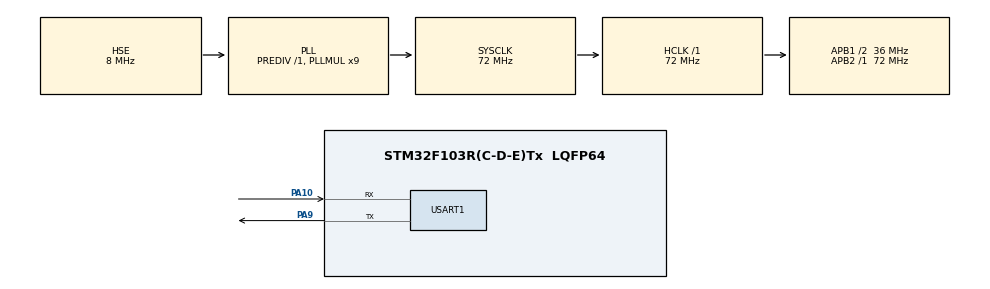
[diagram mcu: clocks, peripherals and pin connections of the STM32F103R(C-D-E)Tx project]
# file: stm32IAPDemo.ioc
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ADC1.Channel-0\#ChannelRegularConversion=ADC_CHANNEL_TEMPSENSOR
ADC1.ContinuousConvMode=ENABLE
ADC1.NbrOfConversionFlag=1
ADC1.Rank-0\#ChannelRegularConversion=1
ADC1.SamplingTime-0\#ChannelRegularConversion=ADC_SAMPLETIME_239CYCLES_5
ADC1.master=1
Dma.ADC1.0.Direction=DMA_PERIPH_TO_MEMORY
Dma.ADC1.0.Instance=DMA1_Channel1
Dma.ADC1.0.MemDataAlignment=DMA_MDATAALIGN_WORD
Dma.ADC1.0.MemInc=DMA_MINC_ENABLE
Dma.ADC1.0.Mode=DMA_NORMAL
Dma.ADC1.0.PeriphDataAlignment=DMA_PDATAALIGN_HALFWORD
Dma.ADC1.0.PeriphInc=DMA_PINC_DISABLE
Dma.ADC1.0.Priority=DMA_PRIORITY_LOW
Dma.Request0=ADC1
FREERTOS.Queues01=cmdRxQueue,512,uint8_t,0,Static,cmdRxQueueBuffer,cmdRxQueueControlBlock;cmdTxQueue,512,uint8_t,0,Static,cmdTxQueueBuffer,cmdTxQueueControlBlock
FREERTOS.Tasks01=defaultTask,24,128,StartDefaultTask,Default,NULL,Dynamic,NULL,NULL;taskParseCmd,40,1024,StartTaskParseCmd,Default,NULL,Dynamic,NULL,NULL;taskFeedWD,55,128,StartTaskFeedWD,Default,NULL,Dynamic,NULL,NULL
FREERTOS.Timers01=cmdReceiveTimeout,CmdReceiveTimeoutCallback,osTimerOnce,Default,NULL,Static,cmdReceiveTimeoutControlBlock
FREERTOS.configTOTAL_HEAP_SIZE=10240
IWDG.Prescaler=IWDG_PRESCALER_32
Mcu.Family=STM32F1
Mcu.Name=STM32F103R(C-D-E)Tx
Mcu.Package=LQFP64
NVIC.DMA1_Channel1_IRQn=true\:5\:0\:false\:false\:true\:true\:false\:true
NVIC.PriorityGroup=NVIC_PRIORITYGROUP_4
NVIC.TIM1_UP_IRQn=true\:0\:0\:false\:false\:true\:false\:false\:true
NVIC.TimeBase=TIM1_UP_IRQn
NVIC.TimeBaseIP=TIM1
NVIC.USART1_IRQn=true\:5\:0\:false\:false\:true\:true\:true\:true
PA10.GPIO_PuPd=GPIO_PULLUP
PA10.Mode=Asynchronous
PA10.Signal=USART1_RX
PA13.Mode=JTAG_5_pins
PA13.Signal=SYS_JTMS-SWDIO
PA14.Mode=JTAG_5_pins
PA14.Signal=SYS_JTCK-SWCLK
PA15.Mode=JTAG_5_pins
PA15.Signal=SYS_JTDI
PA9.Mode=Asynchronous
PA9.Signal=USART1_TX
PB3.Mode=JTAG_5_pins
PB3.Signal=SYS_JTDO-TRACESWO
PB4.Mode=JTAG_5_pins
PB4.Signal=SYS_NJTRST
PD0-OSC_IN.Mode=HSE-External-Oscillator
PD0-OSC_IN.Signal=RCC_OSC_IN
PD1-OSC_OUT.Mode=HSE-External-Oscillator
PD1-OSC_OUT.Signal=RCC_OSC_OUT
ProjectManager.HeapSize=0x200
ProjectManager.StackSize=0x400
ProjectManager.TargetToolchain=MDK-ARM V5.27
RCC.ADCPresc=RCC_ADCPCLK2_DIV6
RCC.AHBFreq_Value=72000000
RCC.APB1CLKDivider=RCC_HCLK_DIV2
RCC.APB1Freq_Value=36000000
RCC.APB1TimFreq_Value=72000000
RCC.APB2Freq_Value=72000000
RCC.APB2TimFreq_Value=72000000
RCC.HCLKFreq_Value=72000000
RCC.PLLMUL=RCC_PLL_MUL9
RCC.PLLSourceVirtual=RCC_PLLSOURCE_HSE
RCC.SYSCLKFreq_VALUE=72000000
RCC.SYSCLKSource=RCC_SYSCLKSOURCE_PLLCLK
RCC.USBFreq_Value=72000000
USART1.VirtualMode=VM_ASYNC
VP_ADC1_TempSens_Input.Mode=IN-TempSens
VP_FREERTOS_VS_CMSIS_V2.Mode=CMSIS_V2
VP_IWDG_VS_IWDG.Mode=IWDG_Activate
VP_RTC_VS_RTC_Activate.Mode=RTC_Enabled
VP_RTC_VS_RTC_Calendar.Mode=RTC_Calendar
VP_SYS_VS_tim1.Mode=TIM1
board=custom

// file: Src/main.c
/* USER CODE BEGIN Header */
/**
  ******************************************************************************
  * @file           : main.c
  * @brief          : Main program body
  ******************************************************************************
  * @attention
  *
  * <h2><center>&copy; Copyright (c) 2020 STMicroelectronics.
  * All rights reserved.</center></h2>
  *
  * This software component is licensed by ST under Ultimate Liberty license
  * SLA0044, the "License"; You may not use this file except in compliance with
  * the License. You may obtain a copy of the License at:
  *                             www.st.com/SLA0044
  *
  ******************************************************************************
  */
/* USER CODE END Header */

#include "main.h"
#include "cmsis_os.h"
#include "adc.h"
#include "dma.h"
#include "iwdg.h"
#include "rtc.h"
#include "usart.h"
#include "gpio.h"

void SystemClock_Config(void);
void MX_FREERTOS_Init(void);

int main(void)
{
  /* USER CODE BEGIN 1 */
	#ifndef BOOTLOADER_APPLICATION
		SCB->VTOR = APPLICATION_ADDRESS;
	#endif
  /* USER CODE END 1 */

  /* MCU Configuration--------------------------------------------------------*/

  /* Reset of all peripherals, Initializes the Flash interface and the Systick. */
  HAL_Init();

  /* Configure the system clock */
  SystemClock_Config();

  /* Initialize all configured peripherals */
  MX_GPIO_Init();
  MX_USART1_UART_Init();
  MX_RTC_Init();
  MX_IWDG_Init();
  MX_DMA_Init();
  MX_ADC1_Init();
  /* USER CODE BEGIN 2 */
	#ifdef BOOTLOADER_APPLICATION
	CheckUpdate();
	#endif
	// https://controllerstech.com/how-to-read-multichannel-adc-in-stm32/
	// https://controllerstech.com/stm32-adc-multi-channels/
	HAL_ADCEx_Calibration_Start(&hadc1); // we need to start the calibration before the adc start
	HAL_ADC_Start_DMA (&hadc1, &temperature_adc, 1);
	LL_USART_EnableIT_RXNE(USART1);
  /* USER CODE END 2 */

  /* Call init function for freertos objects (in freertos.c) */
  MX_FREERTOS_Init();

  /* Start scheduler */
  osKernelStart();

  /* We should never get here as control is now taken by the scheduler */

  /* Infinite loop */
  while (1)
  {

  }
}

void SystemClock_Config(void)
{
  RCC_OscInitTypeDef RCC_OscInitStruct = {0};
  RCC_ClkInitTypeDef RCC_ClkInitStruct = {0};
  RCC_PeriphCLKInitTypeDef PeriphClkInit = {0};

  /** Initializes the CPU, AHB and APB busses clocks
  */
  RCC_OscInitStruct.OscillatorType = RCC_OSCILLATORTYPE_LSI|RCC_OSCILLATORTYPE_HSE;
  RCC_OscInitStruct.HSEState = RCC_HSE_ON;
  RCC_OscInitStruct.HSEPredivValue = RCC_HSE_PREDIV_DIV1;
  RCC_OscInitStruct.HSIState = RCC_HSI_ON;
  RCC_OscInitStruct.LSIState = RCC_LSI_ON;
  RCC_OscInitStruct.PLL.PLLState = RCC_PLL_ON;
  RCC_OscInitStruct.PLL.PLLSource = RCC_PLLSOURCE_HSE;
  RCC_OscInitStruct.PLL.PLLMUL = RCC_PLL_MUL9;
  if (HAL_RCC_OscConfig(&RCC_OscInitStruct) != HAL_OK)
  {
    Error_Handler();
  }
  /** Initializes the CPU, AHB and APB busses clocks
  */
  RCC_ClkInitStruct.ClockType = RCC_CLOCKTYPE_HCLK|RCC_CLOCKTYPE_SYSCLK
                              |RCC_CLOCKTYPE_PCLK1|RCC_CLOCKTYPE_PCLK2;
  RCC_ClkInitStruct.SYSCLKSource = RCC_SYSCLKSOURCE_PLLCLK;
  RCC_ClkInitStruct.AHBCLKDivider = RCC_SYSCLK_DIV1;
  RCC_ClkInitStruct.APB1CLKDivider = RCC_HCLK_DIV2;
  RCC_ClkInitStruct.APB2CLKDivider = RCC_HCLK_DIV1;

  if (HAL_RCC_ClockConfig(&RCC_ClkInitStruct, FLASH_LATENCY_2) != HAL_OK)
  {
    Error_Handler();
  }
  PeriphClkInit.PeriphClockSelection = RCC_PERIPHCLK_RTC|RCC_PERIPHCLK_ADC;
  PeriphClkInit.RTCClockSelection = RCC_RTCCLKSOURCE_LSI;
  PeriphClkInit.AdcClockSelection = RCC_ADCPCLK2_DIV6;
  if (HAL_RCCEx_PeriphCLKConfig(&PeriphClkInit) != HAL_OK)
  {
    Error_Handler();
  }
}

void HAL_TIM_PeriodElapsedCallback(TIM_HandleTypeDef *htim)
{
  if (htim->Instance == TIM1) {
    HAL_IncTick();
  }
}

void Error_Handler(void)
{
}

/************************ (C) COPYRIGHT STMicroelectronics *****END OF FILE****/

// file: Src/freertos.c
/* USER CODE BEGIN Header */
/**
  ******************************************************************************
  * File Name          : freertos.c
  * Description        : Code for freertos applications
  ******************************************************************************
  * @attention
  *
  * <h2><center>&copy; Copyright (c) 2020 STMicroelectronics.
  * All rights reserved.</center></h2>
  *
  * This software component is licensed by ST under Ultimate Liberty license
  * SLA0044, the "License"; You may not use this file except in compliance with
  * the License. You may obtain a copy of the License at:
  *                             www.st.com/SLA0044
  *
  ******************************************************************************
  */
/* USER CODE END Header */

#include "FreeRTOS.h"
#include "task.h"
#include "main.h"
#include "cmsis_os.h"

typedef StaticQueue_t osStaticMessageQDef_t;
typedef StaticTimer_t osStaticTimerDef_t;
osThreadId_t defaultTaskHandle;
osThreadId_t taskParseCmdHandle;
osThreadId_t taskFeedWDHandle;
osMessageQueueId_t cmdRxQueueHandle;
uint8_t cmdRxQueueBuffer[ 512 * sizeof( uint8_t ) ];
osStaticMessageQDef_t cmdRxQueueControlBlock;
osMessageQueueId_t cmdTxQueueHandle;
uint8_t cmdTxQueueBuffer[ 512 * sizeof( uint8_t ) ];
osStaticMessageQDef_t cmdTxQueueControlBlock;
osTimerId_t cmdReceiveTimeoutHandle;
osStaticTimerDef_t cmdReceiveTimeoutControlBlock;

void StartDefaultTask(void *argument);
void StartTaskParseCmd(void *argument);
void StartTaskFeedWD(void *argument);
void CmdReceiveTimeoutCallback(void *argument);

void MX_FREERTOS_Init(void); /* (MISRA C 2004 rule 8.1) */

void MX_FREERTOS_Init(void) {
osKernelInitialize();

  /* Create the timer(s) */
  /* definition and creation of cmdReceiveTimeout */
  const osTimerAttr_t cmdReceiveTimeout_attributes = {
    .name = "cmdReceiveTimeout",
    .cb_mem = &cmdReceiveTimeoutControlBlock,
    .cb_size = sizeof(cmdReceiveTimeoutControlBlock),
  };
  cmdReceiveTimeoutHandle = osTimerNew(CmdReceiveTimeoutCallback, osTimerOnce, NULL, &cmdReceiveTimeout_attributes);

  /* Create the queue(s) */
  /* definition and creation of cmdRxQueue */
  const osMessageQueueAttr_t cmdRxQueue_attributes = {
    .name = "cmdRxQueue",
    .cb_mem = &cmdRxQueueControlBlock,
    .cb_size = sizeof(cmdRxQueueControlBlock),
    .mq_mem = &cmdRxQueueBuffer,
    .mq_size = sizeof(cmdRxQueueBuffer)
  };
  cmdRxQueueHandle = osMessageQueueNew (512, sizeof(uint8_t), &cmdRxQueue_attributes);

  /* definition and creation of cmdTxQueue */
  const osMessageQueueAttr_t cmdTxQueue_attributes = {
    .name = "cmdTxQueue",
    .cb_mem = &cmdTxQueueControlBlock,
    .cb_size = sizeof(cmdTxQueueControlBlock),
    .mq_mem = &cmdTxQueueBuffer,
    .mq_size = sizeof(cmdTxQueueBuffer)
  };
  cmdTxQueueHandle = osMessageQueueNew (512, sizeof(uint8_t), &cmdTxQueue_attributes);

  /* Create the thread(s) */
  /* definition and creation of defaultTask */
  const osThreadAttr_t defaultTask_attributes = {
    .name = "defaultTask",
    .priority = (osPriority_t) osPriorityNormal,
    .stack_size = 128
  };
  defaultTaskHandle = osThreadNew(StartDefaultTask, NULL, &defaultTask_attributes);

  /* definition and creation of taskParseCmd */
  const osThreadAttr_t taskParseCmd_attributes = {
    .name = "taskParseCmd",
    .priority = (osPriority_t) osPriorityHigh,
    .stack_size = 1024
  };
  taskParseCmdHandle = osThreadNew(StartTaskParseCmd, NULL, &taskParseCmd_attributes);

  /* definition and creation of taskFeedWD */
  const osThreadAttr_t taskFeedWD_attributes = {
    .name = "taskFeedWD",
    .priority = (osPriority_t) osPriorityRealtime7,
    .stack_size = 128
  };
  taskFeedWDHandle = osThreadNew(StartTaskFeedWD, NULL, &taskFeedWD_attributes);

}

void StartDefaultTask(void *argument)
{
  /* USER CODE BEGIN StartDefaultTask */
  /* Infinite loop */
  for(;;)
  {
    osDelay(100);
  }
  /* USER CODE END StartDefaultTask */
}

void StartTaskParseCmd(void *argument)
{
  /* USER CODE BEGIN StartTaskParseCmd */
  /* Infinite loop */
  process_command_task();
  /* USER CODE END StartTaskParseCmd */
}

void StartTaskFeedWD(void *argument)
{
  /* USER CODE BEGIN StartTaskFeedWD */
  /* Infinite loop */
  for(;;)
  {
		FeedWDG();
    osDelay(1);
  }
  /* USER CODE END StartTaskFeedWD */
}

/* CmdReceiveTimeoutCallback function */
void CmdReceiveTimeoutCallback(void *argument)
{
  /* USER CODE BEGIN CmdReceiveTimeoutCallback */
	ClearCmd();
  /* USER CODE END CmdReceiveTimeoutCallback */
}

/************************ (C) COPYRIGHT STMicroelectronics *****END OF FILE****/
